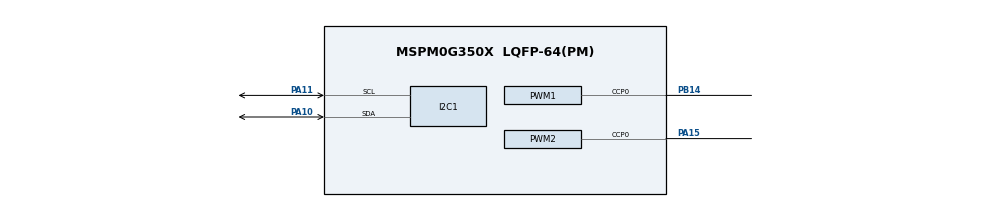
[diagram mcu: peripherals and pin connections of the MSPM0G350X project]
/**
 * @cliArgs --device "MSPM0G350X" --part "Default" --package "LQFP-64(PM)" --product "mspm0_sdk@2.10.00.04"
 * @versions {"tool":"1.26.2+4477"}
 */

/**
 * Import the modules used in this configuration.
 */
const GPIO   = scripting.addModule("/ti/driverlib/GPIO", {}, false);
const GPIO1  = GPIO.addInstance();
const GPIO2  = GPIO.addInstance();
const PWM    = scripting.addModule("/ti/driverlib/PWM", {}, false);
const PWM1   = PWM.addInstance();
const PWM2   = PWM.addInstance();
const SYSCTL = scripting.addModule("/ti/driverlib/SYSCTL");

/**
 * Write custom configuration values to the imported modules.
 */
GPIO1.$name                   = "STEP_MOTOR_A";
GPIO1.associatedPins.create(2);
GPIO1.associatedPins[0].$name = "DIR1";
GPIO1.associatedPins[1].$name = "EN1";

const Board = scripting.addModule("/ti/driverlib/Board", {}, false);

GPIO2.$name                   = "STEP_MOTOR_B";
GPIO2.associatedPins.create(2);
GPIO2.associatedPins[0].$name = "DIR2";
GPIO2.associatedPins[1].$name = "EN2";

PWM1.$name                      = "PWM_0";
PWM1.ccIndex                    = [0];
PWM1.PWM_CHANNEL_0.$name        = "ti_driverlib_pwm_PWMTimerCC0";
PWM1.ccp0PinConfig.$name        = "ti_driverlib_gpio_GPIOPinGeneric0";
PWM1.peripheral.ccp0Pin.$assign = "PB14";

PWM2.$name                      = "PWM_1";
PWM2.ccIndex                    = [0];
PWM2.PWM_CHANNEL_0.$name        = "ti_driverlib_pwm_PWMTimerCC1";
PWM2.ccp0PinConfig.$name        = "ti_driverlib_gpio_GPIOPinGeneric1";
PWM2.peripheral.ccp0Pin.$assign = "PA15";

const I2C  = scripting.addModule("/ti/driverlib/I2C", {}, false);
const I2C1 = I2C.addInstance();
I2C1.$name                     = "I2C_0";
I2C1.peripheral.sdaPin.$assign = "PA10";
I2C1.peripheral.sclPin.$assign = "PA11";

SYSCTL.forceDefaultClkConfig = true;
SYSCTL.clockTreeEn           = true;

/**
 * Pinmux solution for unlocked pins/peripherals. This ensures that minor changes to the automatic solver in a future
 * version of the tool will not impact the pinmux you originally saw.  These lines can be completely deleted in order to
 * re-solve from scratch.
 */
GPIO1.associatedPins[0].pin.$suggestSolution = "PB13";
GPIO1.associatedPins[1].pin.$suggestSolution = "PB15";
Board.peripheral.$suggestSolution            = "DEBUGSS";
Board.peripheral.swclkPin.$suggestSolution   = "PA20";
Board.peripheral.swdioPin.$suggestSolution   = "PA19";
GPIO2.associatedPins[0].pin.$suggestSolution = "PB16";
GPIO2.associatedPins[1].pin.$suggestSolution = "PA12";
PWM1.peripheral.$suggestSolution             = "TIMA0";
PWM2.peripheral.$suggestSolution             = "TIMA1";
I2C1.peripheral.$suggestSolution              = "I2C0";
I2C1.peripheral.sdaPin.$suggestSolution       = "PA10";
I2C1.peripheral.sclPin.$suggestSolution       = "PA11";
